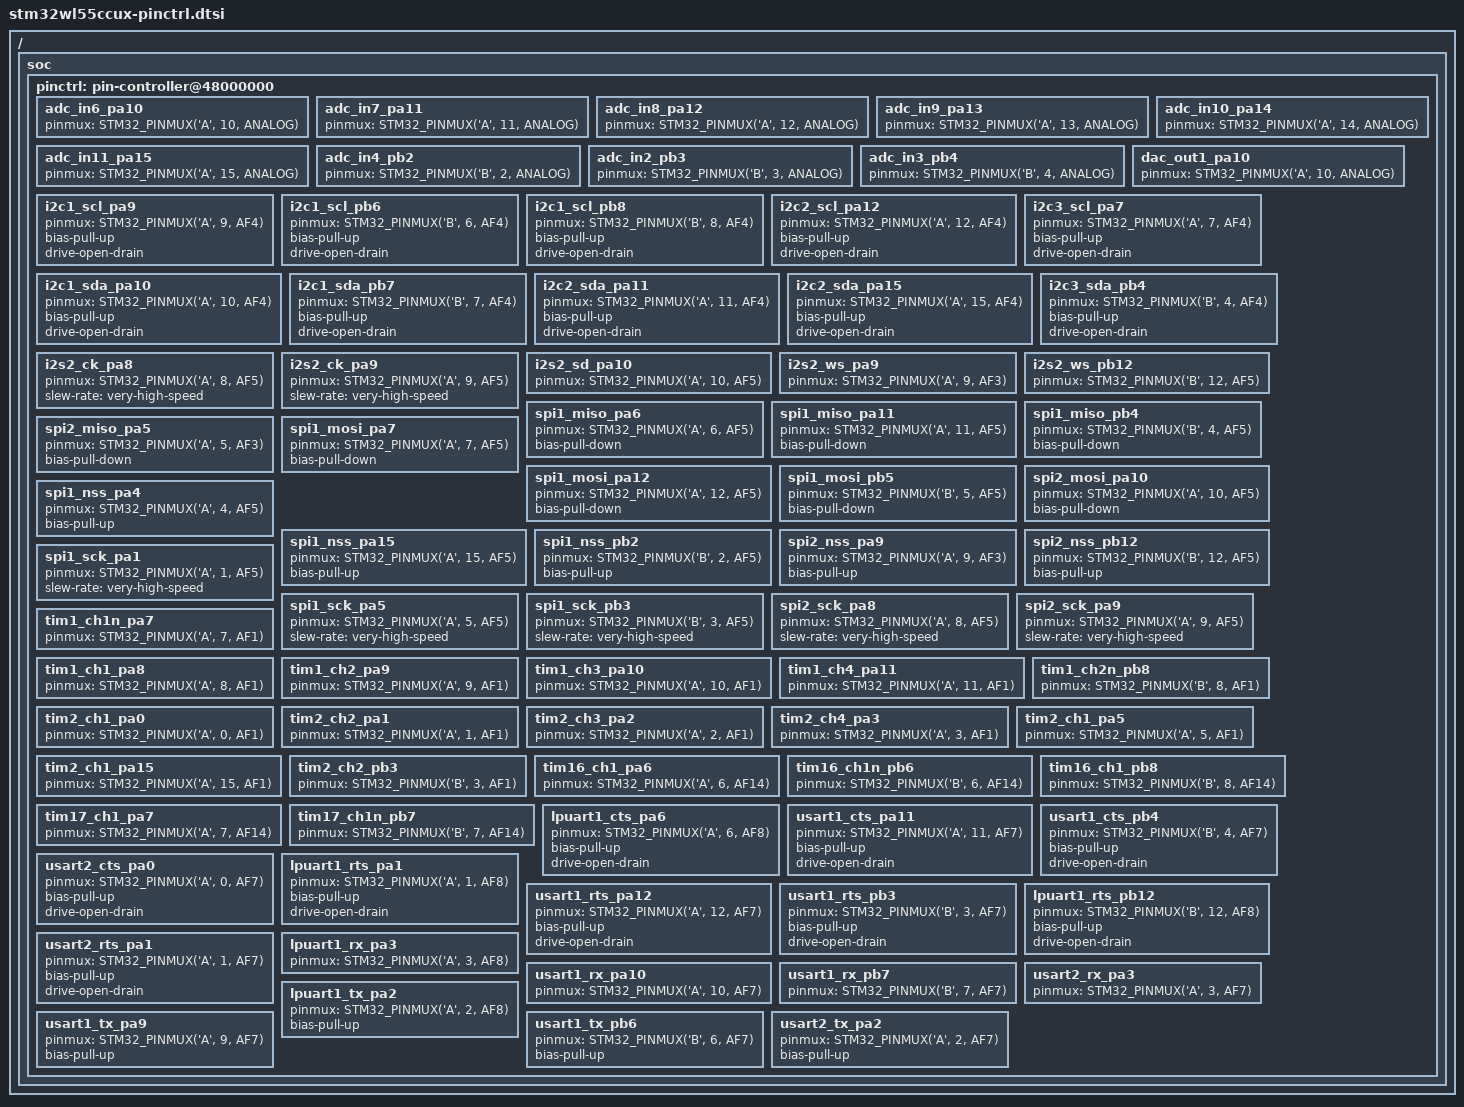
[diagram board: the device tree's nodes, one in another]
/*
 * NOTE: Autogenerated file using genpinctrl.py
 *
 * SPDX-License-Identifier: Apache-2.0
 */

#include <dt-bindings/pinctrl/stm32-pinctrl.h>

/ {
	soc {
		pinctrl: pin-controller@48000000 {

			/* ADC_IN / ADC_INN / ADC_INP */

			adc_in6_pa10: adc_in6_pa10 {
				pinmux = <STM32_PINMUX('A', 10, ANALOG)>;
			};

			adc_in7_pa11: adc_in7_pa11 {
				pinmux = <STM32_PINMUX('A', 11, ANALOG)>;
			};

			adc_in8_pa12: adc_in8_pa12 {
				pinmux = <STM32_PINMUX('A', 12, ANALOG)>;
			};

			adc_in9_pa13: adc_in9_pa13 {
				pinmux = <STM32_PINMUX('A', 13, ANALOG)>;
			};

			adc_in10_pa14: adc_in10_pa14 {
				pinmux = <STM32_PINMUX('A', 14, ANALOG)>;
			};

			adc_in11_pa15: adc_in11_pa15 {
				pinmux = <STM32_PINMUX('A', 15, ANALOG)>;
			};

			adc_in4_pb2: adc_in4_pb2 {
				pinmux = <STM32_PINMUX('B', 2, ANALOG)>;
			};

			adc_in2_pb3: adc_in2_pb3 {
				pinmux = <STM32_PINMUX('B', 3, ANALOG)>;
			};

			adc_in3_pb4: adc_in3_pb4 {
				pinmux = <STM32_PINMUX('B', 4, ANALOG)>;
			};

			/* DAC_OUT */

			dac_out1_pa10: dac_out1_pa10 {
				pinmux = <STM32_PINMUX('A', 10, ANALOG)>;
			};

			/* I2C_SCL */

			i2c1_scl_pa9: i2c1_scl_pa9 {
				pinmux = <STM32_PINMUX('A', 9, AF4)>;
				bias-pull-up;
				drive-open-drain;
			};

			i2c1_scl_pb6: i2c1_scl_pb6 {
				pinmux = <STM32_PINMUX('B', 6, AF4)>;
				bias-pull-up;
				drive-open-drain;
			};

			i2c1_scl_pb8: i2c1_scl_pb8 {
				pinmux = <STM32_PINMUX('B', 8, AF4)>;
				bias-pull-up;
				drive-open-drain;
			};

			i2c2_scl_pa12: i2c2_scl_pa12 {
				pinmux = <STM32_PINMUX('A', 12, AF4)>;
				bias-pull-up;
				drive-open-drain;
			};

			i2c3_scl_pa7: i2c3_scl_pa7 {
				pinmux = <STM32_PINMUX('A', 7, AF4)>;
				bias-pull-up;
				drive-open-drain;
			};

			/* I2C_SDA */

			i2c1_sda_pa10: i2c1_sda_pa10 {
				pinmux = <STM32_PINMUX('A', 10, AF4)>;
				bias-pull-up;
				drive-open-drain;
			};

			i2c1_sda_pb7: i2c1_sda_pb7 {
				pinmux = <STM32_PINMUX('B', 7, AF4)>;
				bias-pull-up;
				drive-open-drain;
			};

			i2c2_sda_pa11: i2c2_sda_pa11 {
				pinmux = <STM32_PINMUX('A', 11, AF4)>;
				bias-pull-up;
				drive-open-drain;
			};

			i2c2_sda_pa15: i2c2_sda_pa15 {
				pinmux = <STM32_PINMUX('A', 15, AF4)>;
				bias-pull-up;
				drive-open-drain;
			};

			i2c3_sda_pb4: i2c3_sda_pb4 {
				pinmux = <STM32_PINMUX('B', 4, AF4)>;
				bias-pull-up;
				drive-open-drain;
			};

			/* I2S_CK */

			i2s2_ck_pa8: i2s2_ck_pa8 {
				pinmux = <STM32_PINMUX('A', 8, AF5)>;
				slew-rate = "very-high-speed";
			};

			i2s2_ck_pa9: i2s2_ck_pa9 {
				pinmux = <STM32_PINMUX('A', 9, AF5)>;
				slew-rate = "very-high-speed";
			};

			/* I2S_SD */

			i2s2_sd_pa10: i2s2_sd_pa10 {
				pinmux = <STM32_PINMUX('A', 10, AF5)>;
			};

			/* I2S_WS */

			i2s2_ws_pa9: i2s2_ws_pa9 {
				pinmux = <STM32_PINMUX('A', 9, AF3)>;
			};

			i2s2_ws_pb12: i2s2_ws_pb12 {
				pinmux = <STM32_PINMUX('B', 12, AF5)>;
			};

			/* SPI_MISO */

			spi1_miso_pa6: spi1_miso_pa6 {
				pinmux = <STM32_PINMUX('A', 6, AF5)>;
				bias-pull-down;
			};

			spi1_miso_pa11: spi1_miso_pa11 {
				pinmux = <STM32_PINMUX('A', 11, AF5)>;
				bias-pull-down;
			};

			spi1_miso_pb4: spi1_miso_pb4 {
				pinmux = <STM32_PINMUX('B', 4, AF5)>;
				bias-pull-down;
			};

			spi2_miso_pa5: spi2_miso_pa5 {
				pinmux = <STM32_PINMUX('A', 5, AF3)>;
				bias-pull-down;
			};

			/* SPI_MOSI */

			spi1_mosi_pa7: spi1_mosi_pa7 {
				pinmux = <STM32_PINMUX('A', 7, AF5)>;
				bias-pull-down;
			};

			spi1_mosi_pa12: spi1_mosi_pa12 {
				pinmux = <STM32_PINMUX('A', 12, AF5)>;
				bias-pull-down;
			};

			spi1_mosi_pb5: spi1_mosi_pb5 {
				pinmux = <STM32_PINMUX('B', 5, AF5)>;
				bias-pull-down;
			};

			spi2_mosi_pa10: spi2_mosi_pa10 {
				pinmux = <STM32_PINMUX('A', 10, AF5)>;
				bias-pull-down;
			};

			/* SPI_NSS */

			spi1_nss_pa4: spi1_nss_pa4 {
				pinmux = <STM32_PINMUX('A', 4, AF5)>;
				bias-pull-up;
			};

			spi1_nss_pa15: spi1_nss_pa15 {
				pinmux = <STM32_PINMUX('A', 15, AF5)>;
				bias-pull-up;
			};

			spi1_nss_pb2: spi1_nss_pb2 {
				pinmux = <STM32_PINMUX('B', 2, AF5)>;
				bias-pull-up;
			};

			spi2_nss_pa9: spi2_nss_pa9 {
				pinmux = <STM32_PINMUX('A', 9, AF3)>;
				bias-pull-up;
			};

			spi2_nss_pb12: spi2_nss_pb12 {
				pinmux = <STM32_PINMUX('B', 12, AF5)>;
				bias-pull-up;
			};

			/* SPI_SCK */

			spi1_sck_pa1: spi1_sck_pa1 {
				pinmux = <STM32_PINMUX('A', 1, AF5)>;
				slew-rate = "very-high-speed";
			};

			spi1_sck_pa5: spi1_sck_pa5 {
				pinmux = <STM32_PINMUX('A', 5, AF5)>;
				slew-rate = "very-high-speed";
			};

			spi1_sck_pb3: spi1_sck_pb3 {
				pinmux = <STM32_PINMUX('B', 3, AF5)>;
				slew-rate = "very-high-speed";
			};

			spi2_sck_pa8: spi2_sck_pa8 {
				pinmux = <STM32_PINMUX('A', 8, AF5)>;
				slew-rate = "very-high-speed";
			};

			spi2_sck_pa9: spi2_sck_pa9 {
				pinmux = <STM32_PINMUX('A', 9, AF5)>;
				slew-rate = "very-high-speed";
			};

			/* TIM_CH / TIM_CHN */

			tim1_ch1n_pa7: tim1_ch1n_pa7 {
				pinmux = <STM32_PINMUX('A', 7, AF1)>;
			};

			tim1_ch1_pa8: tim1_ch1_pa8 {
				pinmux = <STM32_PINMUX('A', 8, AF1)>;
			};

			tim1_ch2_pa9: tim1_ch2_pa9 {
				pinmux = <STM32_PINMUX('A', 9, AF1)>;
			};

			tim1_ch3_pa10: tim1_ch3_pa10 {
				pinmux = <STM32_PINMUX('A', 10, AF1)>;
			};

			tim1_ch4_pa11: tim1_ch4_pa11 {
				pinmux = <STM32_PINMUX('A', 11, AF1)>;
			};

			tim1_ch2n_pb8: tim1_ch2n_pb8 {
				pinmux = <STM32_PINMUX('B', 8, AF1)>;
			};

			tim2_ch1_pa0: tim2_ch1_pa0 {
				pinmux = <STM32_PINMUX('A', 0, AF1)>;
			};

			tim2_ch2_pa1: tim2_ch2_pa1 {
				pinmux = <STM32_PINMUX('A', 1, AF1)>;
			};

			tim2_ch3_pa2: tim2_ch3_pa2 {
				pinmux = <STM32_PINMUX('A', 2, AF1)>;
			};

			tim2_ch4_pa3: tim2_ch4_pa3 {
				pinmux = <STM32_PINMUX('A', 3, AF1)>;
			};

			tim2_ch1_pa5: tim2_ch1_pa5 {
				pinmux = <STM32_PINMUX('A', 5, AF1)>;
			};

			tim2_ch1_pa15: tim2_ch1_pa15 {
				pinmux = <STM32_PINMUX('A', 15, AF1)>;
			};

			tim2_ch2_pb3: tim2_ch2_pb3 {
				pinmux = <STM32_PINMUX('B', 3, AF1)>;
			};

			tim16_ch1_pa6: tim16_ch1_pa6 {
				pinmux = <STM32_PINMUX('A', 6, AF14)>;
			};

			tim16_ch1n_pb6: tim16_ch1n_pb6 {
				pinmux = <STM32_PINMUX('B', 6, AF14)>;
			};

			tim16_ch1_pb8: tim16_ch1_pb8 {
				pinmux = <STM32_PINMUX('B', 8, AF14)>;
			};

			tim17_ch1_pa7: tim17_ch1_pa7 {
				pinmux = <STM32_PINMUX('A', 7, AF14)>;
			};

			tim17_ch1n_pb7: tim17_ch1n_pb7 {
				pinmux = <STM32_PINMUX('B', 7, AF14)>;
			};

			/* UART_CTS / USART_CTS / LPUART_CTS */

			lpuart1_cts_pa6: lpuart1_cts_pa6 {
				pinmux = <STM32_PINMUX('A', 6, AF8)>;
				bias-pull-up;
				drive-open-drain;
			};

			usart1_cts_pa11: usart1_cts_pa11 {
				pinmux = <STM32_PINMUX('A', 11, AF7)>;
				bias-pull-up;
				drive-open-drain;
			};

			usart1_cts_pb4: usart1_cts_pb4 {
				pinmux = <STM32_PINMUX('B', 4, AF7)>;
				bias-pull-up;
				drive-open-drain;
			};

			usart2_cts_pa0: usart2_cts_pa0 {
				pinmux = <STM32_PINMUX('A', 0, AF7)>;
				bias-pull-up;
				drive-open-drain;
			};

			/* UART_RTS / USART_RTS / LPUART_RTS */

			lpuart1_rts_pa1: lpuart1_rts_pa1 {
				pinmux = <STM32_PINMUX('A', 1, AF8)>;
				bias-pull-up;
				drive-open-drain;
			};

			usart1_rts_pa12: usart1_rts_pa12 {
				pinmux = <STM32_PINMUX('A', 12, AF7)>;
				bias-pull-up;
				drive-open-drain;
			};

			usart1_rts_pb3: usart1_rts_pb3 {
				pinmux = <STM32_PINMUX('B', 3, AF7)>;
				bias-pull-up;
				drive-open-drain;
			};

			lpuart1_rts_pb12: lpuart1_rts_pb12 {
				pinmux = <STM32_PINMUX('B', 12, AF8)>;
				bias-pull-up;
				drive-open-drain;
			};

			usart2_rts_pa1: usart2_rts_pa1 {
				pinmux = <STM32_PINMUX('A', 1, AF7)>;
				bias-pull-up;
				drive-open-drain;
			};

			/* UART_RX / USART_RX / LPUART_RX */

			lpuart1_rx_pa3: lpuart1_rx_pa3 {
				pinmux = <STM32_PINMUX('A', 3, AF8)>;
			};

			usart1_rx_pa10: usart1_rx_pa10 {
				pinmux = <STM32_PINMUX('A', 10, AF7)>;
			};

			usart1_rx_pb7: usart1_rx_pb7 {
				pinmux = <STM32_PINMUX('B', 7, AF7)>;
			};

			usart2_rx_pa3: usart2_rx_pa3 {
				pinmux = <STM32_PINMUX('A', 3, AF7)>;
			};

			/* UART_TX / USART_TX / LPUART_TX */

			lpuart1_tx_pa2: lpuart1_tx_pa2 {
				pinmux = <STM32_PINMUX('A', 2, AF8)>;
				bias-pull-up;
			};

			usart1_tx_pa9: usart1_tx_pa9 {
				pinmux = <STM32_PINMUX('A', 9, AF7)>;
				bias-pull-up;
			};

			usart1_tx_pb6: usart1_tx_pb6 {
				pinmux = <STM32_PINMUX('B', 6, AF7)>;
				bias-pull-up;
			};

			usart2_tx_pa2: usart2_tx_pa2 {
				pinmux = <STM32_PINMUX('A', 2, AF7)>;
				bias-pull-up;
			};

		};
	};
};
